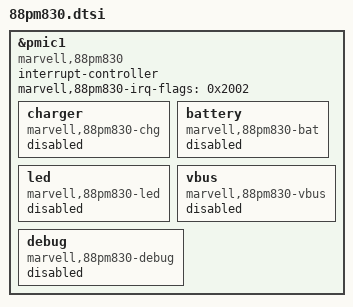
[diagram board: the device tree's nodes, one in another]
/*
 * Copyright (C) 2014 Marvell
 * Yi Zhang <yizhang@marvell.com>
 */

/*
 * Integrated Power Management Chip
 * header file for Marvell charger/fuel gauge/camera flash chip: 88pm830
 */

&pmic1 {
	compatible = "marvell,88pm830";
	interrupt-controller;
	#interrupt-cells = <1>;

	/* IRQF_ONESHOT | IRQF_TRIGGER_FALLING */
	marvell,88pm830-irq-flags =  <0x2002>;

	charger {
		compatible = "marvell,88pm830-chg";

		status = "disabled";
	};

	battery {
		compatible = "marvell,88pm830-bat";

		status = "disabled";
	};

	led {
		compatible = "marvell,88pm830-led";

		status = "disabled";
	};

	vbus {
		compatible = "marvell,88pm830-vbus";

		status = "disabled";
	};

	debug {
		compatible = "marvell,88pm830-debug";

		status = "disabled";
	};
};
